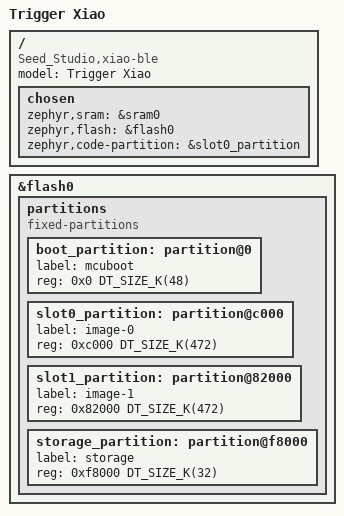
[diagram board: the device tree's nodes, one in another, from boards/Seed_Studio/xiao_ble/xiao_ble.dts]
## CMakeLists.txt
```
cmake_minimum_required(VERSION 3.20.0)
find_package(Zephyr REQUIRED HINTS $ENV{ZEPHYR_BASE})

project(Trigger01)

target_sources(app PRIVATE
	src/adc_trigger.c
	src/drum_config.c
	src/main.c
	src/sample_engine.c
	src/trigger_engine.c
	src/wav_trigger.c
)
```

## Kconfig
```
mainmenu "Trigger01 drum engine"

source "Kconfig.zephyr"

menu "Drum trigger engine"

config DRUM_SAADC_STREAM
	bool "Use continuous nrfx SAADC acquisition"
	select NRFX_SAADC
	help
	  Own the nRF52840 SAADC directly so its internal timer and EasyDMA
	  double buffering can provide gap-free, deterministic acquisition.

config DRUM_ADC_SAMPLE_PERIOD_US
	int "SAADC sample period in microseconds"
	default 100
	range 50 100
	help
	  100 us selects 10 kS/s. Change this to 50 us for 20 kS/s after
	  retuning all sample-count-based trigger parameters.

config DRUM_DIAGNOSTICS
	bool "Print one diagnostic line per hit"
	default y

config DRUM_ADC_TIMING_DIAGNOSTICS
	bool "Collect SAADC DMA callback timing statistics"
	default y

config DRUM_FAKE_TRIGGER_TEST
	bool "Generate a fake kick event every two seconds"
	help
	  Exercise the event queue, sample selection, direct Track 1 command,
	  and I2C error reporting without striking the piezo.

config DRUM_PLAYBACK_THREAD_STACK_SIZE
	int "Playback worker stack size"
	default 1536
	range 1024 4096

config DRUM_PLAYBACK_THREAD_PRIORITY
	int "Playback worker preemptive priority"
	default 1
	range 0 15

endmenu
```

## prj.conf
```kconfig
CONFIG_GPIO=y
CONFIG_I2C=y

# We are using nrfx SAADC directly, not Zephyr's ADC driver.
CONFIG_ADC=n
CONFIG_NRFX_SAADC=y

CONFIG_PRINTK=y
CONFIG_THREAD_NAME=y
CONFIG_MAIN_THREAD_PRIORITY=5

CONFIG_DRUM_DIAGNOSTICS=y
CONFIG_DRUM_ADC_TIMING_DIAGNOSTICS=y
CONFIG_DRUM_FAKE_TRIGGER_TEST=n
CONFIG_DRUM_SAADC_STREAM=y

CONFIG_USE_SEGGER_RTT=y
CONFIG_RTT_CONSOLE=y
CONFIG_UART_CONSOLE=n
```

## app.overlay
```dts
#include <zephyr/dt-bindings/adc/adc.h>
#include <zephyr/dt-bindings/adc/nrf-saadc.h>

/ {
	zephyr,user {
		io-channels = <&adc 0>;
	};
};

&adc {
	status = "okay";
	#address-cells = <1>;
	#size-cells = <0>;

	channel@0 {
		reg = <0>;

		/*
		 * XIAO A0 / D0 = nRF52840 P0.02 = SAADC AIN0
		 */
		zephyr,input-positive = <NRF_SAADC_AIN0>;

		/*
		 * nRF SAADC internal reference is 0.6 V.
		 * Gain 1/6 gives an effective full-scale of:
		 *
		 * 0.6 V / (1/6) = 3.6 V
		 *
		 * Good for a 0 V to 3.3 V biased piezo signal.
		 */
		zephyr,gain = "ADC_GAIN_1_6";
		zephyr,reference = "ADC_REF_INTERNAL";
		zephyr,vref-mv = <600>;

		/*
		 * Use a little acquisition time because the piezo front-end is high impedance.
		 */
		zephyr,acquisition-time = <ADC_ACQ_TIME(ADC_ACQ_TIME_MICROSECONDS, 20)>;

		zephyr,resolution = <12>;
		zephyr,oversampling = <0>;
	};
};
```

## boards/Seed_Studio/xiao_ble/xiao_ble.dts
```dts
/dts-v1/;

#include <nordic/nrf52840_qiaa.dtsi>
#include "xiao_ble-pinctrl.dtsi"

/ {
	model = "Trigger Xiao";
	compatible = "Seed_Studio,xiao-ble";

	chosen {
		zephyr,sram = &sram0;
		zephyr,flash = &flash0;
		zephyr,code-partition = &slot0_partition;
	};
};

&flash0 {
	partitions {
		compatible = "fixed-partitions";
		#address-cells = <1>;
		#size-cells = <1>;

		boot_partition: partition@0 {
			label = "mcuboot";
			reg = <0x0 DT_SIZE_K(48)>;
		};

		slot0_partition: partition@c000 {
			label = "image-0";
			reg = <0xc000 DT_SIZE_K(472)>;
		};

		slot1_partition: partition@82000 {
			label = "image-1";
			reg = <0x82000 DT_SIZE_K(472)>;
		};

		storage_partition: partition@f8000 {
			label = "storage";
			reg = <0xf8000 DT_SIZE_K(32)>;
		};
	};
};
```

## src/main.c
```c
// west flash -d build\Trigger01 --runner jlink

#include <stdbool.h>
#include <stdint.h>

#include <zephyr/drivers/gpio.h>
#include <zephyr/kernel.h>
#include <zephyr/sys/printk.h>
#include <zephyr/sys/util.h>

#include "adc_trigger.h"
#include "drum_config.h"
#include "sample_engine.h"
#include "trigger_engine.h"
#include "wav_trigger.h"

#define LED0_NODE DT_ALIAS(led0)

#if !DT_NODE_HAS_STATUS(LED0_NODE, okay)
#error "led0 alias is not defined for this board"
#endif

#define HIT_EVENT_QUEUE_DEPTH         8U
#define WAV_TRIGGER_POWER_UP_DELAY_MS 500U
#define HEALTH_REPORT_PERIOD_MS       5000U
#define SUPERVISOR_PERIOD_MS          250U
#define FAKE_HIT_PERIOD_MS            2000U

K_MSGQ_DEFINE(hit_event_queue, sizeof(struct drum_hit_event), HIT_EVENT_QUEUE_DEPTH,
	      sizeof(uint32_t));

static const struct gpio_dt_spec status_led = GPIO_DT_SPEC_GET(LED0_NODE, gpios);
static struct trigger_engine kick_engine;

#if CONFIG_DRUM_FAKE_TRIGGER_TEST
static uint32_t uptime_us_32(void)
{
	return (uint32_t)k_ticks_to_us_floor64(k_uptime_ticks());
}
#endif

static bool initialize_status_led(void)
{
	int err;

	if (!gpio_is_ready_dt(&status_led)) {
		printk("LED GPIO not ready\n");
		return false;
	}

	err = gpio_pin_configure_dt(&status_led, GPIO_OUTPUT_INACTIVE);
	if (err != 0) {
		printk("LED configure failed: %d\n", err);
		return false;
	}

	return true;
}

static void initialize_wav_trigger(void)
{
	uint16_t num_tracks = 0U;
	int err = wav_trigger_init();

	if (err != 0) {
		printk("I2C not ready for WAV Trigger Pro: %d; acquisition will continue\n", err);
		return;
	}

	printk("I2C ready on XIAO D4/D5\n");

	/* Preserve the proven power-up settling time before probing the module. */
	k_msleep(WAV_TRIGGER_POWER_UP_DELAY_MS);

	err = wav_trigger_get_num_tracks(&num_tracks);
	if (err != 0) {
		printk("WAV Trigger Pro did not respond: %d; acquisition will continue\n", err);
		return;
	}

	printk("WAV Trigger Pro connected; tracks=%u\n", num_tracks);

	err = wav_trigger_stop_all();
	if (err != 0) {
		printk("WAV Trigger Stop All failed: %d\n", err);
	}

	err = wav_trigger_set_output_gain(0);
	if (err != 0) {
		printk("WAV Trigger output gain failed: %d\n", err);
	}
}

static int initialize_trigger_pipeline(void)
{
	int err;

	err = trigger_engine_init(&kick_engine, &kick_trigger_config);
	if (err != 0) {
		printk("Kick trigger configuration invalid: %d\n", err);
		return err;
	}

	err = sample_engine_start(&hit_event_queue, drum_sample_configs, drum_sample_config_count);
	if (err != 0) {
		printk("Sample engine start failed: %d\n", err);
		return err;
	}

#if CONFIG_DRUM_SAADC_STREAM
	err = adc_trigger_init(&kick_engine, &hit_event_queue);
	if (err != 0) {
		printk("SAADC initialization failed: %d\n", err);
		return err;
	}

	err = adc_trigger_start();
	if (err != 0) {
		printk("SAADC start failed: %d\n", err);
		return err;
	}

	printk("ADC ready: A0/AIN0 rate=%uS/s dma=%u samples\n", adc_trigger_get_sample_rate_hz(),
	       adc_trigger_get_dma_buffer_samples());
	printk("Kick baseline settling; trigger will arm without blocking acquisition\n");
#else
	printk("SAADC stream disabled; fake trigger test only\n");
#endif

	return 0;
}

#if CONFIG_DRUM_FAKE_TRIGGER_TEST
static void submit_fake_hit(void)
{
	static const uint8_t velocities[] = {20U, 40U, 70U, 100U, 127U};
	static size_t velocity_index;
	uint32_t timestamp_us = uptime_us_32();
	struct drum_hit_event event = {
		.drum = DRUM_ID_KICK,
		.accept_path = DRUM_HIT_ACCEPT_NORMAL,
		.peak = 1000U,
		.positive_peak = 1000U,
		.onset_delta = -100,
		.onset_history_delta = -300,
		.min_raw = 1000U,
		.max_raw = 1000U,
		.velocity = velocities[velocity_index],
		.timestamp_us = timestamp_us,
		.peak_complete_timestamp_us = timestamp_us,
	};

	if (k_msgq_put(&hit_event_queue, &event, K_NO_WAIT) != 0) {
		printk("Fake hit queue full\n");
	}

	velocity_index = (velocity_index + 1U) % ARRAY_SIZE(velocities);
}
#endif

static void report_health(const struct adc_trigger_stats *adc_stats,
			  const struct trigger_engine_diagnostics *trigger_diagnostics)
{
#if CONFIG_DRUM_ADC_TIMING_DIAGNOSTICS
	printk("ADC health samples=%u raw=%d baseline=%d state=%s dma_dt_us=%u..%u "
	       "queue_drop=%u saadc_err=%u wav_err=%u release=%u release_suppressed=%u "
	       "release_retrigger_accept=%u polarity_reject=%u slope_reject=%u "
	       "last_reject_delta1=%d last_reject_delta3=%d\n",
	       adc_stats->samples_acquired, adc_stats->latest_raw, adc_stats->baseline,
	       trigger_engine_state_name(adc_stats->trigger_state), adc_stats->dma_interval_min_us,
	       adc_stats->dma_interval_max_us, adc_stats->queue_overruns, adc_stats->saadc_errors,
	       wav_trigger_get_error_count(), trigger_diagnostics->release_detected_count,
	       trigger_diagnostics->release_suppressed_count,
	       trigger_diagnostics->release_retrigger_accept_count,
	       trigger_diagnostics->polarity_reject_count, trigger_diagnostics->slope_reject_count,
	       trigger_diagnostics->last_slope_reject_delta1,
	       trigger_diagnostics->last_slope_reject_history_delta);
#else
	ARG_UNUSED(adc_stats);
	ARG_UNUSED(trigger_diagnostics);
#endif
}

int main(void)
{
	struct adc_trigger_stats adc_stats = {0};
	struct trigger_engine_diagnostics trigger_diagnostics = {0};
	uint32_t last_health_report_ms = 0U;
	uint32_t last_fake_hit_ms = 0U;
	uint32_t last_release_sequence = 0U;
	uint32_t previous_queue_overruns = 0U;
	uint32_t previous_saadc_errors = 0U;
	uint32_t previous_wav_errors = 0U;
	bool armed_reported = false;
	bool led_ready;
	int err;

	printk("Trigger01 production kick engine\n");

	led_ready = initialize_status_led();
	initialize_wav_trigger();

	err = initialize_trigger_pipeline();
	if (err != 0) {
		return err;
	}

	while (true) {
		uint32_t now_ms;
		uint32_t wav_errors;

		k_msleep(SUPERVISOR_PERIOD_MS);
		now_ms = (uint32_t)k_uptime_get();

		if (led_ready) {
			(void)gpio_pin_toggle_dt(&status_led);
		}

		adc_trigger_get_stats(&adc_stats);
		trigger_engine_get_diagnostics(&kick_engine, &trigger_diagnostics);
		wav_errors = wav_trigger_get_error_count();

		if (!armed_reported && adc_stats.trigger_armed) {
			armed_reported = true;
			printk("Kick trigger armed: polarity=%s threshold=%u delta1=%u delta%u=%u "
			       "rearm=%u peak_window=%u samples\n",
			       trigger_engine_polarity_name(kick_trigger_config.polarity),
			       kick_trigger_config.trigger_threshold,
			       kick_trigger_config.onset_slope_threshold,
			       kick_trigger_config.slope_history_samples,
			       kick_trigger_config.onset_history_slope_threshold,
			       kick_trigger_config.rearm_threshold,
			       kick_trigger_config.peak_window_samples);
			printk("Kick release recovery: threshold=%u slope=%u retrigger_delta%u=%u "
			       "rearm=%u guard=%u stable=%u baseline_gate=%u samples\n",
			       kick_trigger_config.release_threshold,
			       kick_trigger_config.release_slope_threshold,
			       kick_trigger_config.slope_history_samples,
			       kick_trigger_config.retrigger_slope_threshold,
			       kick_trigger_config.release_rearm_threshold,
			       kick_trigger_config.release_guard_samples,
			       kick_trigger_config.release_stable_samples,
			       kick_trigger_config.baseline_track_threshold);
		}

#if CONFIG_DRUM_DIAGNOSTICS
		if (trigger_diagnostics.release_sequence != last_release_sequence) {
			last_release_sequence = trigger_diagnostics.release_sequence;
			printk("KICK RELEASE initial=%d release_peak=%u release_slope=%u "
			       "neg_ring=%u ring_slope1=%u ring_slope3=%u recovery_us=%u count=%u "
			       "suppressed=%u retrigger_accept=%u\n",
			       trigger_diagnostics.last_release_initial_centered,
			       trigger_diagnostics.last_release_peak,
			       trigger_diagnostics.last_release_max_slope,
			       trigger_diagnostics.last_release_ringback_peak,
			       trigger_diagnostics.last_release_ringback_slope1,
			       trigger_diagnostics.last_release_ringback_history_slope,
			       trigger_diagnostics.last_release_recovery_us,
			       trigger_diagnostics.release_detected_count,
			       trigger_diagnostics.release_suppressed_count,
			       trigger_diagnostics.release_retrigger_accept_count);
		}
#else
		ARG_UNUSED(last_release_sequence);
#endif

		if (adc_stats.queue_overruns != previous_queue_overruns) {
			printk("Hit-event queue overrun count=%u\n", adc_stats.queue_overruns);
			previous_queue_overruns = adc_stats.queue_overruns;
		}

		if (adc_stats.saadc_errors != previous_saadc_errors) {
			printk("SAADC stream error count=%u\n", adc_stats.saadc_errors);
			previous_saadc_errors = adc_stats.saadc_errors;
		}

		if (wav_errors != previous_wav_errors) {
			printk("WAV Trigger I2C error count=%u\n", wav_errors);
			previous_wav_errors = wav_errors;
		}

		if ((now_ms - last_health_report_ms) >= HEALTH_REPORT_PERIOD_MS) {
			last_health_report_ms = now_ms;
			report_health(&adc_stats, &trigger_diagnostics);
		}

#if CONFIG_DRUM_FAKE_TRIGGER_TEST
		if ((now_ms - last_fake_hit_ms) >= FAKE_HIT_PERIOD_MS) {
			last_fake_hit_ms = now_ms;
			submit_fake_hit();
		}
#else
		ARG_UNUSED(last_fake_hit_ms);
#endif
	}

	return 0;
}
```

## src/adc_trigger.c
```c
#include "adc_trigger.h"

#include <errno.h>
#include <zephyr/sys/util.h>

#if CONFIG_DRUM_SAADC_STREAM

#include <limits.h>

#include <nrfx_saadc.h>
#include <zephyr/devicetree.h>
#include <zephyr/drivers/adc.h>
#include <zephyr/dt-bindings/adc/nrf-saadc.h>
#include <zephyr/sys/atomic.h>

#define ADC_DEVICE_NODE  DT_NODELABEL(adc)
#define ADC_CHANNEL_NODE DT_CHILD(ADC_DEVICE_NODE, channel_0)

#define ADC_SAMPLE_PERIOD_US      ((uint32_t)CONFIG_DRUM_ADC_SAMPLE_PERIOD_US)
#define ADC_SAMPLE_RATE_HZ        (1000000U / ADC_SAMPLE_PERIOD_US)
#define ADC_DMA_BUFFER_SAMPLES    8U
#define SAADC_TIMER_FREQUENCY_MHZ 16U
#define SAADC_TIMER_CC            ((ADC_SAMPLE_PERIOD_US * SAADC_TIMER_FREQUENCY_MHZ) - 1U)

BUILD_ASSERT(DT_NODE_HAS_STATUS(ADC_DEVICE_NODE, okay), "SAADC must be enabled");
BUILD_ASSERT(DT_NODE_EXISTS(ADC_CHANNEL_NODE), "SAADC channel@0 must exist");
BUILD_ASSERT(DT_PROP(ADC_CHANNEL_NODE, zephyr_input_positive) == NRF_SAADC_AIN0,
	     "kick input must remain on AIN0 / P0.02");
BUILD_ASSERT(DT_STRING_TOKEN(ADC_CHANNEL_NODE, zephyr_gain) == ADC_GAIN_1_6,
	     "kick SAADC gain must remain 1/6");
BUILD_ASSERT(DT_STRING_TOKEN(ADC_CHANNEL_NODE, zephyr_reference) == ADC_REF_INTERNAL,
	     "kick SAADC must use the internal reference");
BUILD_ASSERT(ADC_ACQ_TIME_UNIT(DT_PROP(ADC_CHANNEL_NODE, zephyr_acquisition_time)) ==
		     ADC_ACQ_TIME_MICROSECONDS,
	     "kick SAADC acquisition time must be in microseconds");
BUILD_ASSERT(ADC_ACQ_TIME_VALUE(DT_PROP(ADC_CHANNEL_NODE, zephyr_acquisition_time)) == 20U,
	     "kick SAADC acquisition time must remain 20 us");
BUILD_ASSERT(DT_PROP(ADC_CHANNEL_NODE, zephyr_resolution) == 12U,
	     "kick SAADC resolution must remain 12-bit");
BUILD_ASSERT(DT_PROP(ADC_CHANNEL_NODE, zephyr_oversampling) == 0U,
	     "continuous kick acquisition currently requires no oversampling");
BUILD_ASSERT((1000000U % ADC_SAMPLE_PERIOD_US) == 0U,
	     "sample period must produce an integer sample rate");
BUILD_ASSERT(ADC_SAMPLE_PERIOD_US <= NRFX_SAADC_INTERNAL_TIMER_INTERVAL_MAX_US,
	     "sample period exceeds the SAADC internal timer range");
BUILD_ASSERT(SAADC_TIMER_CC <= UINT16_MAX, "SAADC internal timer compare does not fit");

struct adc_runtime {
	struct trigger_engine *engine;
	struct k_msgq *hit_queue;
	atomic_t samples_acquired;
	atomic_t dma_buffers_processed;
	atomic_t queue_overruns;
	atomic_t saadc_errors;
	atomic_t dma_interval_min_us;
	atomic_t dma_interval_max_us;
	atomic_t latest_raw;
	atomic_t baseline;
	atomic_t trigger_state;
	atomic_t trigger_armed;
	uint32_t previous_done_cycle;
	uint8_t next_buffer_index;
	bool have_previous_done_cycle;
	bool initialized;
	bool started;
};

static struct adc_runtime runtime;
static nrf_saadc_value_t sample_buffers[2][ADC_DMA_BUFFER_SAMPLES];

static uint32_t uptime_us_32(void)
{
	return (uint32_t)k_ticks_to_us_floor64(k_uptime_ticks());
}

static void atomic_update_min(atomic_t *target, uint32_t value)
{
	atomic_val_t previous = atomic_get(target);

	while ((value < (uint32_t)previous) && !atomic_cas(target, previous, (atomic_val_t)value)) {
		previous = atomic_get(target);
	}
}

static void atomic_update_max(atomic_t *target, uint32_t value)
{
	atomic_val_t previous = atomic_get(target);

	while ((value > (uint32_t)previous) && !atomic_cas(target, previous, (atomic_val_t)value)) {
		previous = atomic_get(target);
	}
}

static void record_dma_timing(void)
{
#if CONFIG_DRUM_ADC_TIMING_DIAGNOSTICS
	uint32_t now_cycle = k_cycle_get_32();

	if (runtime.have_previous_done_cycle) {
		uint32_t interval_us = k_cyc_to_us_floor32(now_cycle - runtime.previous_done_cycle);

		atomic_update_min(&runtime.dma_interval_min_us, interval_us);
		atomic_update_max(&runtime.dma_interval_max_us, interval_us);
	}

	runtime.previous_done_cycle = now_cycle;
	runtime.have_previous_done_cycle = true;
#endif
}

static void process_completed_buffer(const nrfx_saadc_done_evt_t *done)
{
	uint32_t sample_timestamp_us =
		uptime_us_32() - (((uint32_t)done->size - 1U) * ADC_SAMPLE_PERIOD_US);

	record_dma_timing();

	for (uint16_t i = 0U; i < done->size; ++i) {
		struct drum_hit_event event;
		int16_t raw = (int16_t)NRFX_SAADC_SAMPLE_GET(done->p_buffer, i);

		/* Match Zephyr's single-ended ADC behavior for rare sub-ground noise. */
		if (raw < 0) {
			raw = 0;
		}

		if (trigger_engine_process_sample(runtime.engine, raw, sample_timestamp_us,
						  &event)) {
			if (k_msgq_put(runtime.hit_queue, &event, K_NO_WAIT) != 0) {
				atomic_inc(&runtime.queue_overruns);
			}
		}

		sample_timestamp_us += ADC_SAMPLE_PERIOD_US;
		atomic_set(&runtime.latest_raw, raw);
	}

	atomic_add(&runtime.samples_acquired, done->size);
	atomic_inc(&runtime.dma_buffers_processed);
	atomic_set(&runtime.baseline, trigger_engine_get_baseline(runtime.engine));
	atomic_set(&runtime.trigger_state, trigger_engine_get_state(runtime.engine));
	atomic_set(&runtime.trigger_armed, trigger_engine_is_armed(runtime.engine));
}

static void saadc_event_handler(const nrfx_saadc_evt_t *event)
{
	int err;

	switch (event->type) {
	case NRFX_SAADC_EVT_READY:
		/* Sampling is now paced entirely by the SAADC internal timer. */
		break;

	case NRFX_SAADC_EVT_BUF_REQ:
		err = nrfx_saadc_buffer_set(sample_buffers[runtime.next_buffer_index],
					    ADC_DMA_BUFFER_SAMPLES);
		if (err != 0) {
			atomic_inc(&runtime.saadc_errors);
		} else {
			runtime.next_buffer_index ^= 1U;
		}
		break;

	case NRFX_SAADC_EVT_DONE:
		process_completed_buffer(&event->data.done);
		break;

	case NRFX_SAADC_EVT_FINISHED:
		/* Continuous mode should only finish if a replacement buffer was missed. */
		atomic_inc(&runtime.saadc_errors);
		break;

	default:
		break;
	}
}

int adc_trigger_init(struct trigger_engine *engine, struct k_msgq *hit_queue)
{
	nrfx_saadc_channel_t channel = NRFX_SAADC_DEFAULT_CHANNEL_SE(
		DT_PROP(ADC_CHANNEL_NODE, zephyr_input_positive), DT_REG_ADDR(ADC_CHANNEL_NODE));
	nrfx_saadc_adv_config_t advanced_config = NRFX_SAADC_DEFAULT_ADV_CONFIG;
	int err;

	if ((engine == NULL) || (hit_queue == NULL)) {
		return -EINVAL;
	}

	runtime = (struct adc_runtime){
		.engine = engine,
		.hit_queue = hit_queue,
		.dma_interval_min_us = ATOMIC_INIT(INT_MAX),
		.next_buffer_index = 1U,
	};

	/*
	 * We own the SAADC directly through nrfx, therefore
	 * we must connect the peripheral IRQ ourselves.
	 */
	IRQ_CONNECT(DT_IRQN(ADC_DEVICE_NODE),
	    DT_IRQ(ADC_DEVICE_NODE, priority),
	    nrfx_isr,
	    nrfx_saadc_irq_handler,
	    0);

	err = nrfx_saadc_init(0U);
	if (err != 0) {
		return err;
	}

	/* Blocking calibration is acceptable during initialization, before sampling starts. */
	err = nrfx_saadc_offset_calibrate(NULL);
	if (err != 0) {
		goto fail;
	}

	channel.channel_config.gain = NRF_SAADC_GAIN1_6;
	channel.channel_config.reference = NRF_SAADC_REFERENCE_INTERNAL;
	channel.channel_config.acq_time = NRF_SAADC_ACQTIME_20US;
	channel.channel_config.mode = NRF_SAADC_MODE_SINGLE_ENDED;
	channel.channel_config.burst = NRF_SAADC_BURST_DISABLED;

	err = nrfx_saadc_channel_config(&channel);
	if (err != 0) {
		goto fail;
	}

	advanced_config.internal_timer_cc = (uint16_t)SAADC_TIMER_CC;
	advanced_config.start_on_end = true;

	err = nrfx_saadc_advanced_mode_set(BIT(DT_REG_ADDR(ADC_CHANNEL_NODE)),
					   NRF_SAADC_RESOLUTION_12BIT, &advanced_config,
					   saadc_event_handler);
	if (err != 0) {
		goto fail;
	}

	err = nrfx_saadc_buffer_set(sample_buffers[0], ADC_DMA_BUFFER_SAMPLES);
	if (err != 0) {
		goto fail;
	}

	runtime.initialized = true;
	return 0;

fail:
	nrfx_saadc_uninit();
	return err;
}

int adc_trigger_start(void)
{
	int err;

	if (!runtime.initialized) {
		return -EACCES;
	}

	if (runtime.started) {
		return -EALREADY;
	}

	err = nrfx_saadc_mode_trigger();
	if (err != 0) {
		return err;
	}

	runtime.started = true;
	return 0;
}

void adc_trigger_get_stats(struct adc_trigger_stats *stats)
{
	uint32_t minimum;

	if (stats == NULL) {
		return;
	}

	minimum = (uint32_t)atomic_get(&runtime.dma_interval_min_us);
	if (minimum == (uint32_t)INT_MAX) {
		minimum = 0U;
	}

	*stats = (struct adc_trigger_stats){
		.samples_acquired = (uint32_t)atomic_get(&runtime.samples_acquired),
		.dma_buffers_processed = (uint32_t)atomic_get(&runtime.dma_buffers_processed),
		.queue_overruns = (uint32_t)atomic_get(&runtime.queue_overruns),
		.saadc_errors = (uint32_t)atomic_get(&runtime.saadc_errors),
		.dma_interval_min_us = minimum,
		.dma_interval_max_us = (uint32_t)atomic_get(&runtime.dma_interval_max_us),
		.latest_raw = (int16_t)atomic_get(&runtime.latest_raw),
		.baseline = (int16_t)atomic_get(&runtime.baseline),
		.trigger_state = (enum trigger_state)atomic_get(&runtime.trigger_state),
		.trigger_armed = atomic_get(&runtime.trigger_armed) != 0,
	};
}

uint32_t adc_trigger_get_sample_rate_hz(void)
{
	return ADC_SAMPLE_RATE_HZ;
}

uint16_t adc_trigger_get_dma_buffer_samples(void)
{
	return ADC_DMA_BUFFER_SAMPLES;
}

#else

int adc_trigger_init(struct trigger_engine *engine, struct k_msgq *hit_queue)
{
	ARG_UNUSED(engine);
	ARG_UNUSED(hit_queue);
	return -ENOTSUP;
}

int adc_trigger_start(void)
{
	return -ENOTSUP;
}

void adc_trigger_get_stats(struct adc_trigger_stats *stats)
{
	if (stats != NULL) {
		*stats = (struct adc_trigger_stats){0};
	}
}

uint32_t adc_trigger_get_sample_rate_hz(void)
{
	return 0U;
}

uint16_t adc_trigger_get_dma_buffer_samples(void)
{
	return 0U;
}

#endif /* CONFIG_DRUM_SAADC_STREAM */
```

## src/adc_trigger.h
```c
#ifndef ADC_TRIGGER_H_
#define ADC_TRIGGER_H_

#include <stdbool.h>
#include <stdint.h>

#include <zephyr/kernel.h>

#include "trigger_engine.h"

struct adc_trigger_stats {
	uint32_t samples_acquired;
	uint32_t dma_buffers_processed;
	uint32_t queue_overruns;
	uint32_t saadc_errors;
	uint32_t dma_interval_min_us;
	uint32_t dma_interval_max_us;
	int16_t latest_raw;
	int16_t baseline;
	enum trigger_state trigger_state;
	bool trigger_armed;
};

int adc_trigger_init(struct trigger_engine *engine, struct k_msgq *hit_queue);
int adc_trigger_start(void);
void adc_trigger_get_stats(struct adc_trigger_stats *stats);
uint32_t adc_trigger_get_sample_rate_hz(void);
uint16_t adc_trigger_get_dma_buffer_samples(void);

#endif /* ADC_TRIGGER_H_ */
```

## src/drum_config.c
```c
#include "drum_config.h"

#include <zephyr/sys/util.h>

/*
 * 128-entry velocity curve generated as:
 *   velocity = round(1 + 126 * pow(index / 127, 0.75))
 *
 * The lookup occurs once per completed hit, so the sample path uses no float.
 * Replace this table to audition another response curve without touching the
 * detector or sample-selection code.
 */
static const uint8_t kick_velocity_curve_gamma_075[] = {
	1U,   4U,   7U,   9U,   10U,  12U,  14U,  15U,  17U,  18U,  20U,  21U,  22U,  24U,  25U,
	26U,  28U,  29U,  30U,  31U,  32U,  34U,  35U,  36U,  37U,  38U,  39U,  40U,  42U,  43U,
	44U,  45U,  46U,  47U,  48U,  49U,  50U,  51U,  52U,  53U,  54U,  55U,  56U,  57U,  58U,
	59U,  60U,  61U,  62U,  63U,  64U,  65U,  65U,  66U,  67U,  68U,  69U,  70U,  71U,  72U,
	73U,  74U,  75U,  75U,  76U,  77U,  78U,  79U,  80U,  81U,  82U,  82U,  83U,  84U,  85U,
	86U,  87U,  88U,  88U,  89U,  90U,  91U,  92U,  93U,  93U,  94U,  95U,  96U,  97U,  98U,
	98U,  99U,  100U, 101U, 102U, 102U, 103U, 104U, 105U, 106U, 106U, 107U, 108U, 109U, 109U,
	110U, 111U, 112U, 113U, 113U, 114U, 115U, 116U, 116U, 117U, 118U, 119U, 119U, 120U, 121U,
	122U, 123U, 123U, 124U, 125U, 126U, 126U, 127U,
};

const struct drum_trigger_config kick_trigger_config = {
	.drum = DRUM_ID_KICK,
	.polarity = TRIGGER_POLARITY_NEGATIVE,
	.trigger_threshold = 700U,
	.rearm_threshold = 300U,
	/* Initial separation derived from real kick/ringback RTT measurements. */
	.onset_slope_threshold = 80U,
	.onset_history_slope_threshold = 180U,
	.retrigger_slope_threshold = 300U,
	.slope_history_samples = 3U, /* delta3 spans 300 us at 10 kS/s */
	.release_threshold = 500U,
	.release_slope_threshold = 10U,
	.release_rearm_threshold = 300U,
	.release_guard_samples = 80U,  /* 8.0 ms at 10 kS/s */
	.release_stable_samples = 15U, /* 1.5 ms at 10 kS/s */
	.baseline_track_threshold = 100U,
	.adc_clip_low_threshold = 8U,
	.adc_clip_high_threshold = 4087U,
	.peak_window_samples = 20U,       /* 2.0 ms at 10 kS/s */
	.hard_mask_samples = 150U,        /* 15 ms at 10 kS/s */
	.rearm_stable_samples = 15U,      /* 1.5 ms at 10 kS/s */
	.baseline_settle_samples = 1000U, /* 100 ms at 10 kS/s */
	.velocity_min_peak = 800U,
	.velocity_max_peak = 1800U,
	.baseline_filter_shift = 11U, /* quiet baseline alpha = 1/2048 */
	.velocity_curve = kick_velocity_curve_gamma_075,
	.velocity_curve_size = ARRAY_SIZE(kick_velocity_curve_gamma_075),
};

/* Track 1 (0001.wav) is the complete initial kick library. */
static const uint16_t kick_all_tracks[] = {1U};

static const struct velocity_layer kick_layers[] = {
	{
		.velocity_min = 1U,
		.velocity_max = 127U,
		.tracks = kick_all_tracks,
		.track_count = ARRAY_SIZE(kick_all_tracks),
		.gain_db = 0,
	},
};

const struct drum_sample_config drum_sample_configs[] = {
	{
		.drum = DRUM_ID_KICK,
		.layers = kick_layers,
		.layer_count = ARRAY_SIZE(kick_layers),
		.velocity_gain =
			{
				.enabled = true,
				.scope = VELOCITY_GAIN_FULL_RANGE,
				.minimum_db = -18,
				.maximum_db = 0,
			},
	},
};

const size_t drum_sample_config_count = ARRAY_SIZE(drum_sample_configs);
```

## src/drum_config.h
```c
#ifndef DRUM_CONFIG_H_
#define DRUM_CONFIG_H_

#include <stddef.h>

#include "sample_engine.h"
#include "trigger_engine.h"

extern const struct drum_trigger_config kick_trigger_config;
extern const struct drum_sample_config drum_sample_configs[];
extern const size_t drum_sample_config_count;

#endif /* DRUM_CONFIG_H_ */
```

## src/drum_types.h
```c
#ifndef DRUM_TYPES_H_
#define DRUM_TYPES_H_

#include <stdbool.h>
#include <stdint.h>

enum drum_id {
	DRUM_ID_KICK = 0,
	DRUM_ID_COUNT,
};

enum drum_hit_accept_path {
	DRUM_HIT_ACCEPT_NORMAL = 0,
	DRUM_HIT_ACCEPT_RELEASE_RECOVERY,
};

struct drum_hit_event {
	enum drum_id drum;
	enum drum_hit_accept_path accept_path;
	uint16_t peak;
	uint16_t positive_peak;
	uint16_t negative_peak;
	int16_t onset_delta;
	int16_t onset_history_delta;
	uint16_t min_raw;
	uint16_t max_raw;
	uint8_t velocity;
	bool clip_low;
	bool clip_high;
	uint32_t timestamp_us;
	uint32_t peak_complete_timestamp_us;
};

#endif /* DRUM_TYPES_H_ */
```

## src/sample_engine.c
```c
#include "sample_engine.h"

#include <errno.h>
#include <stdbool.h>

#include <zephyr/sys/atomic.h>
#include <zephyr/sys/printk.h>

#include "wav_trigger.h"

#define SAMPLE_ENGINE_MAX_LAYERS           8U
#define SAMPLE_ENGINE_MAX_TRACKS_PER_LAYER 32U
#define SAMPLE_ENGINE_TRACK_MIN            1U
#define SAMPLE_ENGINE_TRACK_MAX            4096U
#define SAMPLE_ENGINE_GAIN_MIN_DB          (-80)
#define SAMPLE_ENGINE_GAIN_MAX_DB          0

struct sample_engine_runtime {
	struct k_msgq *hit_queue;
	const struct drum_sample_config *configs;
	size_t config_count;
	uint16_t next_round_robin[DRUM_ID_COUNT][SAMPLE_ENGINE_MAX_LAYERS];
	atomic_t hits_processed;
	atomic_t selection_errors;
	atomic_t playback_errors;
	atomic_t last_command_latency_us;
	atomic_t last_i2c_duration_us;
	bool started;
};

static struct sample_engine_runtime runtime;
static struct k_thread playback_thread;
K_THREAD_STACK_DEFINE(playback_stack, CONFIG_DRUM_PLAYBACK_THREAD_STACK_SIZE);

static uint32_t uptime_us_32(void)
{
	return (uint32_t)k_ticks_to_us_floor64(k_uptime_ticks());
}

static const char *drum_name(enum drum_id drum)
{
	return (drum == DRUM_ID_KICK) ? "KICK" : "UNKNOWN";
}

static const char *accept_path_name(enum drum_hit_accept_path path)
{
	return (path == DRUM_HIT_ACCEPT_RELEASE_RECOVERY) ? "RELEASE" : "NORMAL";
}

static int validate_sample_configs(const struct drum_sample_config *configs, size_t config_count)
{
	bool configured_drums[DRUM_ID_COUNT] = {false};

	if ((configs == NULL) || (config_count == 0U)) {
		return -EINVAL;
	}

	for (size_t drum_index = 0U; drum_index < config_count; ++drum_index) {
		const struct drum_sample_config *config = &configs[drum_index];
		uint16_t expected_velocity = 1U;

		if ((config->drum < 0) || (config->drum >= DRUM_ID_COUNT) ||
		    configured_drums[config->drum] || (config->layers == NULL) ||
		    (config->layer_count == 0U) ||
		    (config->layer_count > SAMPLE_ENGINE_MAX_LAYERS)) {
			return -EINVAL;
		}

		if (config->velocity_gain.enabled &&
		    ((config->velocity_gain.scope < VELOCITY_GAIN_FULL_RANGE) ||
		     (config->velocity_gain.scope > VELOCITY_GAIN_WITHIN_LAYER) ||
		     (config->velocity_gain.minimum_db > config->velocity_gain.maximum_db) ||
		     (config->velocity_gain.minimum_db < SAMPLE_ENGINE_GAIN_MIN_DB) ||
		     (config->velocity_gain.maximum_db > SAMPLE_ENGINE_GAIN_MAX_DB))) {
			return -EINVAL;
		}

		configured_drums[config->drum] = true;

		for (size_t layer_index = 0U; layer_index < config->layer_count; ++layer_index) {
			const struct velocity_layer *layer = &config->layers[layer_index];

			if ((layer->velocity_min != expected_velocity) ||
			    (layer->velocity_max < layer->velocity_min) ||
			    (layer->tracks == NULL) || (layer->track_count == 0U) ||
			    (layer->track_count > SAMPLE_ENGINE_MAX_TRACKS_PER_LAYER) ||
			    (layer->gain_db < SAMPLE_ENGINE_GAIN_MIN_DB) ||
			    (layer->gain_db > SAMPLE_ENGINE_GAIN_MAX_DB)) {
				return -EINVAL;
			}

			if (config->velocity_gain.enabled &&
			    (((int32_t)layer->gain_db + config->velocity_gain.minimum_db <
			      SAMPLE_ENGINE_GAIN_MIN_DB) ||
			     ((int32_t)layer->gain_db + config->velocity_gain.maximum_db >
			      SAMPLE_ENGINE_GAIN_MAX_DB))) {
				return -EINVAL;
			}

			for (size_t track_index = 0U; track_index < layer->track_count;
			     ++track_index) {
				if ((layer->tracks[track_index] < SAMPLE_ENGINE_TRACK_MIN) ||
				    (layer->tracks[track_index] > SAMPLE_ENGINE_TRACK_MAX)) {
					return -EINVAL;
				}
			}

			expected_velocity = (uint16_t)layer->velocity_max + 1U;
		}

		if (expected_velocity != 128U) {
			return -EINVAL;
		}
	}

	return 0;
}

static const struct drum_sample_config *find_drum_config(enum drum_id drum)
{
	for (size_t i = 0U; i < runtime.config_count; ++i) {
		if (runtime.configs[i].drum == drum) {
			return &runtime.configs[i];
		}
	}

	return NULL;
}

static int16_t velocity_gain_db(const struct drum_sample_config *config,
				const struct velocity_layer *layer, uint8_t velocity)
{
	uint8_t velocity_min = 1U;
	uint8_t velocity_max = 127U;
	uint32_t velocity_position;
	uint32_t velocity_range;
	uint32_t gain_range;
	int32_t scaled_gain;

	if (!config->velocity_gain.enabled) {
		return 0;
	}

	if (config->velocity_gain.scope == VELOCITY_GAIN_WITHIN_LAYER) {
		velocity_min = layer->velocity_min;
		velocity_max = layer->velocity_max;
	}

	if (velocity_max == velocity_min) {
		return config->velocity_gain.maximum_db;
	}

	velocity_position = (uint32_t)velocity - velocity_min;
	velocity_range = (uint32_t)velocity_max - velocity_min;
	gain_range = (uint32_t)((int32_t)config->velocity_gain.maximum_db -
				(int32_t)config->velocity_gain.minimum_db);
	scaled_gain = (int32_t)(((velocity_position * gain_range) + (velocity_range / 2U)) /
				velocity_range);

	return (int16_t)((int32_t)config->velocity_gain.minimum_db + scaled_gain);
}

int sample_engine_select(const struct drum_hit_event *event, struct sample_selection *selection)
{
	const struct drum_sample_config *config;

	if ((event == NULL) || (selection == NULL) || !runtime.started || (event->velocity < 1U) ||
	    (event->velocity > 127U)) {
		return -EINVAL;
	}

	config = find_drum_config(event->drum);
	if (config == NULL) {
		return -ENOENT;
	}

	for (size_t layer_index = 0U; layer_index < config->layer_count; ++layer_index) {
		const struct velocity_layer *layer = &config->layers[layer_index];

		if ((event->velocity >= layer->velocity_min) &&
		    (event->velocity <= layer->velocity_max)) {
			uint16_t round_robin = runtime.next_round_robin[event->drum][layer_index];
			int16_t dynamic_gain = velocity_gain_db(config, layer, event->velocity);

			selection->track = layer->tracks[round_robin];
			selection->velocity_gain_db = dynamic_gain;
			selection->gain_db = (int16_t)(layer->gain_db + dynamic_gain);
			selection->layer_index = (uint8_t)layer_index;
			selection->round_robin_index = (uint8_t)round_robin;

			runtime.next_round_robin[event->drum][layer_index] =
				(uint16_t)((round_robin + 1U) % layer->track_count);
			return 0;
		}
	}

	return -ENOENT;
}

static void playback_thread_entry(void *arg1, void *arg2, void *arg3)
{
	struct drum_hit_event event;
	uint32_t previous_hit_timestamp_us = 0U;
	bool have_previous_hit = false;

	ARG_UNUSED(arg1);
	ARG_UNUSED(arg2);
	ARG_UNUSED(arg3);

	while (true) {
		struct sample_selection selection;
		uint32_t command_timestamp_us;
		uint32_t capture_duration_us;
		uint32_t dispatch_latency_us;
		uint32_t command_latency_us;
		uint32_t i2c_duration_us;
		uint32_t hit_interval_ms = 0U;
		int err;

		(void)k_msgq_get(runtime.hit_queue, &event, K_FOREVER);
		atomic_inc(&runtime.hits_processed);

		err = sample_engine_select(&event, &selection);
		if (err != 0) {
			atomic_inc(&runtime.selection_errors);
#if CONFIG_DRUM_DIAGNOSTICS
			printk("%s sample selection failed: %d\n", drum_name(event.drum), err);
#endif
			continue;
		}

		command_timestamp_us = uptime_us_32();
		capture_duration_us = event.peak_complete_timestamp_us - event.timestamp_us;
		dispatch_latency_us = command_timestamp_us - event.peak_complete_timestamp_us;
		command_latency_us = command_timestamp_us - event.timestamp_us;
		err = wav_trigger_play_track(selection.track, selection.gain_db);
		i2c_duration_us = uptime_us_32() - command_timestamp_us;

		atomic_set(&runtime.last_command_latency_us, (atomic_val_t)command_latency_us);
		atomic_set(&runtime.last_i2c_duration_us, (atomic_val_t)i2c_duration_us);

		if (err != 0) {
			atomic_inc(&runtime.playback_errors);
		}

		if (have_previous_hit) {
			hit_interval_ms = (event.timestamp_us - previous_hit_timestamp_us) / 1000U;
		}
		previous_hit_timestamp_us = event.timestamp_us;
		have_previous_hit = true;

#if CONFIG_DRUM_DIAGNOSTICS
		printk("%s peak=%u pos=%u neg=%u vel=%u delta1=%d delta3=%d path=%s "
		       "min_raw=%u max_raw=%u clip_low=%u clip_high=%u layer=%u rr=%u track=%u "
		       "gain_db=%d vel_gain_db=%d dt=%ums capture_us=%u dispatch_us=%u "
		       "latency_us=%u i2c_us=%u err=%d\n",
		       drum_name(event.drum), event.peak, event.positive_peak, event.negative_peak,
		       event.velocity, event.onset_delta, event.onset_history_delta,
		       accept_path_name(event.accept_path), event.min_raw, event.max_raw,
		       event.clip_low, event.clip_high, selection.layer_index,
		       selection.round_robin_index, selection.track, selection.gain_db,
		       selection.velocity_gain_db, hit_interval_ms, capture_duration_us,
		       dispatch_latency_us, command_latency_us, i2c_duration_us, err);
#endif
	}
}

int sample_engine_start(struct k_msgq *hit_queue, const struct drum_sample_config *configs,
			size_t config_count)
{
	int err;

	if ((hit_queue == NULL) || runtime.started) {
		return -EINVAL;
	}

	err = validate_sample_configs(configs, config_count);
	if (err != 0) {
		return err;
	}

	runtime = (struct sample_engine_runtime){
		.hit_queue = hit_queue,
		.configs = configs,
		.config_count = config_count,
		.started = true,
	};

	(void)k_thread_create(&playback_thread, playback_stack,
			      K_THREAD_STACK_SIZEOF(playback_stack), playback_thread_entry, NULL,
			      NULL, NULL, CONFIG_DRUM_PLAYBACK_THREAD_PRIORITY, 0, K_NO_WAIT);
	k_thread_name_set(&playback_thread, "sample_playback");

	return 0;
}

void sample_engine_get_stats(struct sample_engine_stats *stats)
{
	if (stats == NULL) {
		return;
	}

	*stats = (struct sample_engine_stats){
		.hits_processed = (uint32_t)atomic_get(&runtime.hits_processed),
		.selection_errors = (uint32_t)atomic_get(&runtime.selection_errors),
		.playback_errors = (uint32_t)atomic_get(&runtime.playback_errors),
		.last_command_latency_us = (uint32_t)atomic_get(&runtime.last_command_latency_us),
		.last_i2c_duration_us = (uint32_t)atomic_get(&runtime.last_i2c_duration_us),
	};
}
```

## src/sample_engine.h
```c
#ifndef SAMPLE_ENGINE_H_
#define SAMPLE_ENGINE_H_

#include <stdbool.h>
#include <stddef.h>
#include <stdint.h>

#include <zephyr/kernel.h>

#include "drum_types.h"

struct velocity_layer {
	uint8_t velocity_min;
	uint8_t velocity_max;
	const uint16_t *tracks;
	size_t track_count;
	int16_t gain_db;
};

enum velocity_gain_scope {
	VELOCITY_GAIN_FULL_RANGE = 0,
	VELOCITY_GAIN_WITHIN_LAYER,
};

struct velocity_gain_config {
	bool enabled;
	enum velocity_gain_scope scope;
	int16_t minimum_db;
	int16_t maximum_db;
};

struct drum_sample_config {
	enum drum_id drum;
	const struct velocity_layer *layers;
	size_t layer_count;
	struct velocity_gain_config velocity_gain;
};

struct sample_selection {
	uint16_t track;
	int16_t gain_db;
	int16_t velocity_gain_db;
	uint8_t layer_index;
	uint8_t round_robin_index;
};

struct sample_engine_stats {
	uint32_t hits_processed;
	uint32_t selection_errors;
	uint32_t playback_errors;
	uint32_t last_command_latency_us;
	uint32_t last_i2c_duration_us;
};

int sample_engine_start(struct k_msgq *hit_queue, const struct drum_sample_config *configs,
			size_t config_count);

/* Deterministic selection API; advances the selected layer's round-robin state. */
int sample_engine_select(const struct drum_hit_event *event, struct sample_selection *selection);

void sample_engine_get_stats(struct sample_engine_stats *stats);

#endif /* SAMPLE_ENGINE_H_ */
```

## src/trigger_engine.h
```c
#ifndef TRIGGER_ENGINE_H_
#define TRIGGER_ENGINE_H_

#include <stdbool.h>
#include <stddef.h>
#include <stdint.h>

#include "drum_types.h"

#define TRIGGER_SLOPE_HISTORY_MAX_SAMPLES 8U

enum trigger_polarity {
	TRIGGER_POLARITY_NEGATIVE = 0,
	TRIGGER_POLARITY_POSITIVE,
	TRIGGER_POLARITY_BOTH,
};

enum trigger_state {
	TRIGGER_STATE_IDLE = 0,
	TRIGGER_STATE_PEAK_CAPTURE,
	TRIGGER_STATE_HARD_MASK,
	TRIGGER_STATE_REARM,
	TRIGGER_STATE_RELEASE_RECOVERY,
};

struct drum_trigger_config {
	enum drum_id drum;
	enum trigger_polarity polarity;
	/* Amplitudes are centered ADC counts; slopes are counts per sample. */
	uint16_t trigger_threshold;
	uint16_t rearm_threshold;
	uint16_t onset_slope_threshold;
	uint16_t onset_history_slope_threshold;
	uint16_t retrigger_slope_threshold;
	uint8_t slope_history_samples;
	uint16_t release_threshold;
	uint16_t release_slope_threshold;
	uint16_t release_rearm_threshold;
	uint16_t release_guard_samples;
	uint16_t release_stable_samples;
	uint16_t baseline_track_threshold;
	uint16_t adc_clip_low_threshold;
	uint16_t adc_clip_high_threshold;
	uint16_t peak_window_samples;
	uint16_t hard_mask_samples;
	uint16_t rearm_stable_samples;
	uint16_t baseline_settle_samples;
	uint16_t velocity_min_peak;
	uint16_t velocity_max_peak;
	uint8_t baseline_filter_shift;
	const uint8_t *velocity_curve;
	size_t velocity_curve_size;
};

struct trigger_engine_diagnostics {
	uint32_t release_detected_count;
	uint32_t release_suppressed_count;
	uint32_t release_retrigger_accept_count;
	uint32_t polarity_reject_count;
	uint32_t slope_reject_count;
	int16_t last_slope_reject_delta1;
	int16_t last_slope_reject_history_delta;
	uint32_t release_sequence;
	int16_t last_release_initial_centered;
	uint16_t last_release_peak;
	uint16_t last_release_max_slope;
	uint16_t last_release_ringback_peak;
	uint16_t last_release_ringback_slope1;
	uint16_t last_release_ringback_history_slope;
	uint32_t last_release_recovery_us;
};

struct trigger_engine {
	const struct drum_trigger_config *config;
	enum trigger_state state;
	int32_t baseline_q8;
	int32_t previous_centered;
	int32_t centered_history[TRIGGER_SLOPE_HISTORY_MAX_SAMPLES];
	uint32_t threshold_timestamp_us;
	int16_t onset_delta;
	int16_t onset_history_delta;
	enum drum_hit_accept_path accept_path;
	uint16_t positive_peak;
	uint16_t negative_peak;
	uint16_t absolute_peak;
	uint16_t min_raw;
	uint16_t max_raw;
	uint16_t peak_samples;
	uint16_t state_samples;
	uint16_t rearm_stable_samples;
	uint16_t settle_samples;
	uint8_t centered_history_next;
	uint8_t centered_history_count;
	uint32_t release_timestamp_us;
	int16_t release_initial_centered;
	uint16_t release_peak;
	uint16_t release_max_slope;
	uint16_t release_ringback_peak;
	uint16_t release_ringback_slope1;
	uint16_t release_ringback_history_slope;
	struct trigger_engine_diagnostics diagnostics;
	bool baseline_initialized;
	bool previous_centered_valid;
	bool clip_low;
	bool clip_high;
	bool release_ringback_suppressed;
	bool armed;
};

int trigger_engine_init(struct trigger_engine *engine, const struct drum_trigger_config *config);

/*
 * Process exactly one uniformly spaced ADC sample. Returns true only when a
 * completed hit has been written to event_out.
 */
bool trigger_engine_process_sample(struct trigger_engine *engine, int16_t raw,
				   uint32_t timestamp_us, struct drum_hit_event *event_out);

int16_t trigger_engine_get_baseline(const struct trigger_engine *engine);
enum trigger_state trigger_engine_get_state(const struct trigger_engine *engine);
bool trigger_engine_is_armed(const struct trigger_engine *engine);
void trigger_engine_get_diagnostics(const struct trigger_engine *engine,
				    struct trigger_engine_diagnostics *diagnostics);
const char *trigger_engine_state_name(enum trigger_state state);
const char *trigger_engine_polarity_name(enum trigger_polarity polarity);

#endif /* TRIGGER_ENGINE_H_ */
```

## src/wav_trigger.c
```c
#include "wav_trigger.h"

#include <errno.h>
#include <stdbool.h>
#include <stddef.h>

#include <zephyr/device.h>
#include <zephyr/drivers/i2c.h>
#include <zephyr/kernel.h>
#include <zephyr/sys/atomic.h>
#include <zephyr/irq.h>

#define WAV_TRIGGER_I2C_NODE DT_NODELABEL(i2c1)

#if !DT_NODE_HAS_STATUS(WAV_TRIGGER_I2C_NODE, okay)
#error "i2c1 is not enabled in devicetree"
#endif

/* Robertsonics WAV Trigger Pro Qwiic protocol (7-bit address). */
#define WAV_TRIGGER_I2C_ADDRESS         0x13U
#define WAV_TRIGGER_CMD_GET_NUM_TRACKS  2U
#define WAV_TRIGGER_CMD_TRACK_PLAY_POLY 3U
#define WAV_TRIGGER_CMD_STOP_ALL        8U
#define WAV_TRIGGER_CMD_SET_OUTPUT_GAIN 13U

#define WAV_TRIGGER_TRACK_MIN         1U
#define WAV_TRIGGER_TRACK_MAX         4096U
#define WAV_TRIGGER_GAIN_MIN_DB       (-80)
#define WAV_TRIGGER_GAIN_MAX_DB       0
#define WAV_TRIGGER_BALANCE_CENTER    64U
#define WAV_TRIGGER_RESPONSE_DELAY_MS 2U

static const struct device *const i2c_device = DEVICE_DT_GET(WAV_TRIGGER_I2C_NODE);
static atomic_t i2c_error_count;
static bool transport_ready;

static int write_command(const uint8_t *data, size_t length)
{
	if (!transport_ready) {
		atomic_inc(&i2c_error_count);
		return -ENODEV;
	}

	int err = i2c_write(i2c_device, data, length, WAV_TRIGGER_I2C_ADDRESS);

	if (err != 0) {
		atomic_inc(&i2c_error_count);
	}

	return err;
}

static int read_response(uint8_t *data, size_t length)
{
	if (!transport_ready) {
		atomic_inc(&i2c_error_count);
		return -ENODEV;
	}

	int err = i2c_read(i2c_device, data, length, WAV_TRIGGER_I2C_ADDRESS);

	if (err != 0) {
		atomic_inc(&i2c_error_count);
	}

	return err;
}

static void put_le16(uint8_t *destination, int16_t value)
{
	uint16_t raw = (uint16_t)value;

	destination[0] = (uint8_t)(raw & 0xffU);
	destination[1] = (uint8_t)(raw >> 8);
}

int wav_trigger_init(void)
{
	transport_ready = false;
	atomic_set(&i2c_error_count, 0);

	if (!device_is_ready(i2c_device)) {
		return -ENODEV;
	}

	transport_ready = true;
	return 0;
}

int wav_trigger_get_num_tracks(uint16_t *num_tracks)
{
	uint8_t command = WAV_TRIGGER_CMD_GET_NUM_TRACKS;
	uint8_t response[2] = {0};
	int err;

	if (num_tracks == NULL) {
		return -EINVAL;
	}

	err = write_command(&command, sizeof(command));
	if (err != 0) {
		return err;
	}

	/* The playback module prepares its two-byte response after the command ACK. */
	k_msleep(WAV_TRIGGER_RESPONSE_DELAY_MS);

	err = read_response(response, sizeof(response));
	if (err != 0) {
		return err;
	}

	*num_tracks = (uint16_t)response[0] | ((uint16_t)response[1] << 8);
	return 0;
}

int wav_trigger_play_track(uint16_t track, int16_t gain_db)
{
	uint8_t command[11] = {
		WAV_TRIGGER_CMD_TRACK_PLAY_POLY,
		(uint8_t)(track & 0xffU),
		(uint8_t)(track >> 8),
		0U,
		0U,
		WAV_TRIGGER_BALANCE_CENTER,
		0U, /* attack time, LSB */
		0U, /* attack time, MSB */
		0U, /* pitch offset, LSB */
		0U, /* pitch offset, MSB */
		0U, /* no loop, voice lock, or pitch-bend flags */
	};

	if ((track < WAV_TRIGGER_TRACK_MIN) || (track > WAV_TRIGGER_TRACK_MAX)) {
		return -EINVAL;
	}

	if ((gain_db < WAV_TRIGGER_GAIN_MIN_DB) || (gain_db > WAV_TRIGGER_GAIN_MAX_DB)) {
		return -ERANGE;
	}

	put_le16(&command[3], gain_db);
	return write_command(command, sizeof(command));
}

int wav_trigger_stop_all(void)
{
	uint8_t command = WAV_TRIGGER_CMD_STOP_ALL;

	return write_command(&command, sizeof(command));
}

int wav_trigger_set_output_gain(int16_t gain_db)
{
	uint8_t command[3] = {WAV_TRIGGER_CMD_SET_OUTPUT_GAIN, 0U, 0U};

	if ((gain_db < WAV_TRIGGER_GAIN_MIN_DB) || (gain_db > WAV_TRIGGER_GAIN_MAX_DB)) {
		return -ERANGE;
	}

	put_le16(&command[1], gain_db);
	return write_command(command, sizeof(command));
}

uint32_t wav_trigger_get_error_count(void)
{
	return (uint32_t)atomic_get(&i2c_error_count);
}
```

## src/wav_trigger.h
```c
#ifndef WAV_TRIGGER_H_
#define WAV_TRIGGER_H_

#include <stdint.h>

/*
 * Initialize the WAV Trigger Pro transport. This only validates that the
 * Zephyr I2C controller is ready; use wav_trigger_get_num_tracks() to probe
 * the playback module itself.
 */
int wav_trigger_init(void);

/* Query the number of numbered WAV tracks on the microSD card. */
int wav_trigger_get_num_tracks(uint16_t *num_tracks);

/*
 * Start a new, one-shot polyphonic instance of track. Existing voices,
 * including another copy of the same track, are intentionally left playing.
 */
int wav_trigger_play_track(uint16_t track, int16_t gain_db);

int wav_trigger_stop_all(void);
int wav_trigger_set_output_gain(int16_t gain_db);

/* Total failed I2C transfers since boot. */
uint32_t wav_trigger_get_error_count(void);

#endif /* WAV_TRIGGER_H_ */
```
